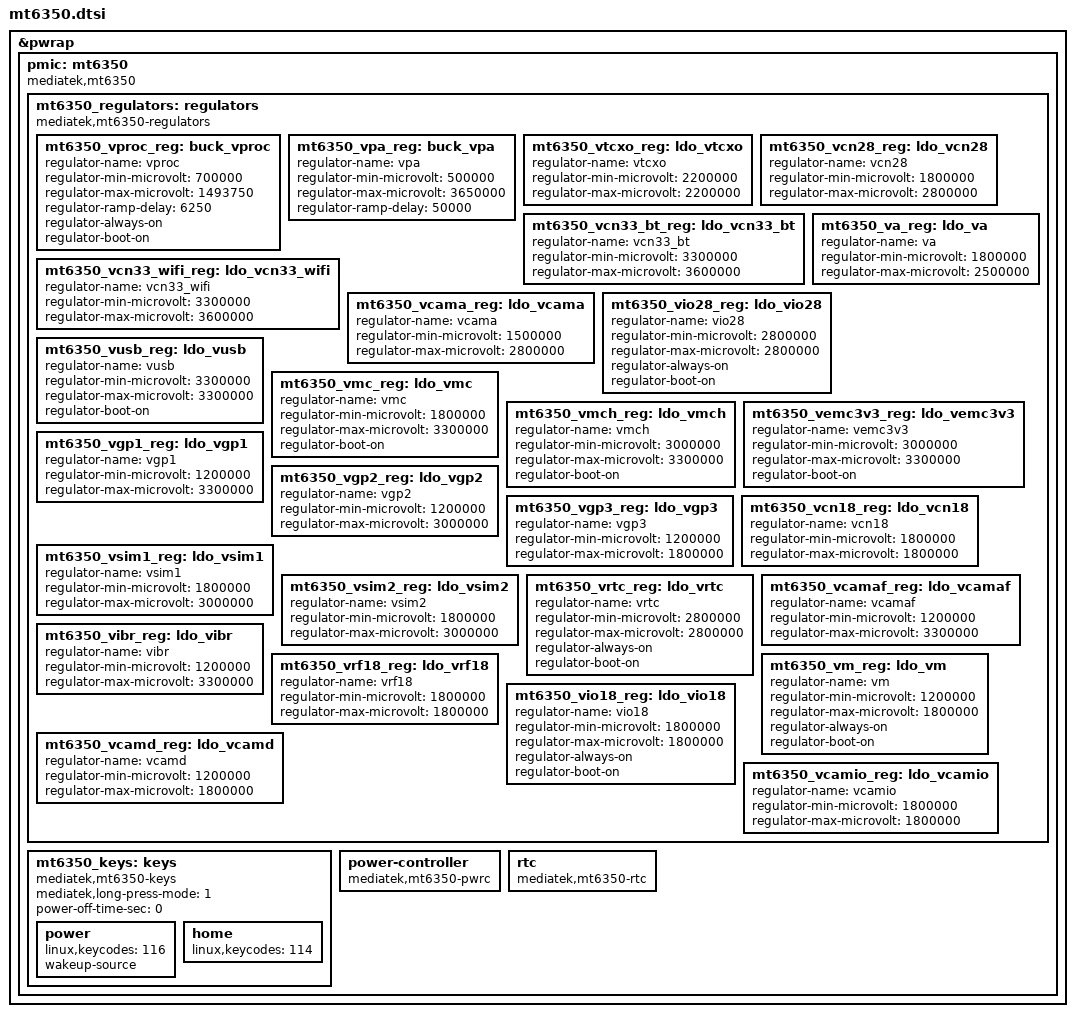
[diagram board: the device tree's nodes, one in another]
// SPDX-License-Identifier: GPL-2.0
/*
 * Copyright (c) 2017-2018 MediaTek Inc.
 * Author: John Crispin <john@phrozen.org>
 *	   Sean Wang <sean.wang@mediatek.com>
 *
 */

/* based on upstream mt6323.dtsi */
&pwrap {
	pmic: mt6350 {
		compatible = "mediatek,mt6350";
	
		mt6350_regulators: regulators {
			compatible = "mediatek,mt6350-regulators";

			mt6350_vproc_reg: buck_vproc {
				regulator-name = "vproc";
				regulator-min-microvolt = <700000>;
				regulator-max-microvolt = <1493750>;
				regulator-ramp-delay = <6250>;
				regulator-always-on;
				regulator-boot-on;
			};
		  
			mt6350_vpa_reg: buck_vpa {
				regulator-name = "vpa";
				regulator-min-microvolt = <500000>;
				regulator-max-microvolt = <3650000>;
				regulator-ramp-delay = <50000>;
			};

			mt6350_vtcxo_reg: ldo_vtcxo {
				regulator-name = "vtcxo";
				regulator-min-microvolt = <2200000>;
				regulator-max-microvolt = <2200000>;
			};

			mt6350_vcn28_reg: ldo_vcn28 {
				regulator-name = "vcn28";
				regulator-min-microvolt = <1800000>;
				regulator-max-microvolt = <2800000>;
			};

			mt6350_vcn33_bt_reg: ldo_vcn33_bt {
				regulator-name = "vcn33_bt";
				regulator-min-microvolt = <3300000>;
				regulator-max-microvolt = <3600000>;
			};

			mt6350_vcn33_wifi_reg: ldo_vcn33_wifi {
				regulator-name = "vcn33_wifi";
				regulator-min-microvolt = <3300000>;
				regulator-max-microvolt = <3600000>;
			};

			mt6350_va_reg: ldo_va {
				regulator-name = "va";
				regulator-min-microvolt = <1800000>;
				regulator-max-microvolt = <2500000>;
			};

			mt6350_vcama_reg: ldo_vcama {
				regulator-name = "vcama";
				regulator-min-microvolt = <1500000>;
				regulator-max-microvolt = <2800000>;
			};

			mt6350_vio28_reg: ldo_vio28 {
				regulator-name = "vio28";
				regulator-min-microvolt = <2800000>;
				regulator-max-microvolt = <2800000>;
				regulator-always-on;
				regulator-boot-on;
			};

			mt6350_vusb_reg: ldo_vusb {
				regulator-name = "vusb";
				regulator-min-microvolt = <3300000>;
				regulator-max-microvolt = <3300000>;
				regulator-boot-on;
			};

			mt6350_vmc_reg: ldo_vmc {
				regulator-name = "vmc";
				regulator-min-microvolt = <1800000>;
				regulator-max-microvolt = <3300000>;
				regulator-boot-on;
			};

			mt6350_vmch_reg: ldo_vmch {
				regulator-name = "vmch";
				regulator-min-microvolt = <3000000>;
				regulator-max-microvolt = <3300000>;
				regulator-boot-on;
			};

			mt6350_vemc3v3_reg: ldo_vemc3v3 {
				regulator-name = "vemc3v3";
				regulator-min-microvolt = <3000000>;
				regulator-max-microvolt = <3300000>;
				regulator-boot-on;
			};

			mt6350_vgp1_reg: ldo_vgp1 {
				regulator-name = "vgp1";
				regulator-min-microvolt = <1200000>;
				regulator-max-microvolt = <3300000>;
			};

			mt6350_vgp2_reg: ldo_vgp2 {
				regulator-name = "vgp2";
				regulator-min-microvolt = <1200000>;
				regulator-max-microvolt = <3000000>;
			};

			mt6350_vgp3_reg: ldo_vgp3 {
				regulator-name = "vgp3";
				regulator-min-microvolt = <1200000>;
				regulator-max-microvolt = <1800000>;
			};

			mt6350_vcn18_reg: ldo_vcn18 {
				regulator-name = "vcn18";
				regulator-min-microvolt = <1800000>;
				regulator-max-microvolt = <1800000>;
			};

			mt6350_vsim1_reg: ldo_vsim1 {
				regulator-name = "vsim1";
				regulator-min-microvolt = <1800000>;
				regulator-max-microvolt = <3000000>;
			};

			mt6350_vsim2_reg: ldo_vsim2 {
				regulator-name = "vsim2";
				regulator-min-microvolt = <1800000>;
				regulator-max-microvolt = <3000000>;
			};

			mt6350_vrtc_reg: ldo_vrtc {
				regulator-name = "vrtc";
				regulator-min-microvolt = <2800000>;
				regulator-max-microvolt = <2800000>;
				regulator-always-on;
				regulator-boot-on;
			};

			mt6350_vcamaf_reg: ldo_vcamaf {
				regulator-name = "vcamaf";
				regulator-min-microvolt = <1200000>;
				regulator-max-microvolt = <3300000>;
			};

			mt6350_vibr_reg: ldo_vibr {
				regulator-name = "vibr";
				regulator-min-microvolt = <1200000>;
				regulator-max-microvolt = <3300000>;
			};

			mt6350_vrf18_reg: ldo_vrf18 {
				regulator-name = "vrf18";
				regulator-min-microvolt = <1800000>;
				regulator-max-microvolt = <1800000>;
			};

			mt6350_vm_reg: ldo_vm {
				regulator-name = "vm";
				regulator-min-microvolt = <1200000>;
				regulator-max-microvolt = <1800000>;
				regulator-always-on;
				regulator-boot-on;
			};

			mt6350_vio18_reg: ldo_vio18 {
				regulator-name = "vio18";
				regulator-min-microvolt = <1800000>;
				regulator-max-microvolt = <1800000>;
				regulator-always-on;
				regulator-boot-on;
			};

			mt6350_vcamd_reg: ldo_vcamd {
				regulator-name = "vcamd";
				regulator-min-microvolt = <1200000>;
				regulator-max-microvolt = <1800000>;
			};

			mt6350_vcamio_reg: ldo_vcamio {
				regulator-name = "vcamio";
				regulator-min-microvolt = <1800000>;
				regulator-max-microvolt = <1800000>;
			};
		};

		mt6350_keys: keys {
			compatible = "mediatek,mt6350-keys";
			mediatek,long-press-mode = <1>;
			power-off-time-sec = <0>;

			power {
				linux,keycodes = <116>;
				wakeup-source;
			};

			home {
				linux,keycodes = <114>;
			};
		};

		power-controller {
			compatible = "mediatek,mt6350-pwrc";
		};

		rtc {
			compatible = "mediatek,mt6350-rtc";
		};
	};
};
